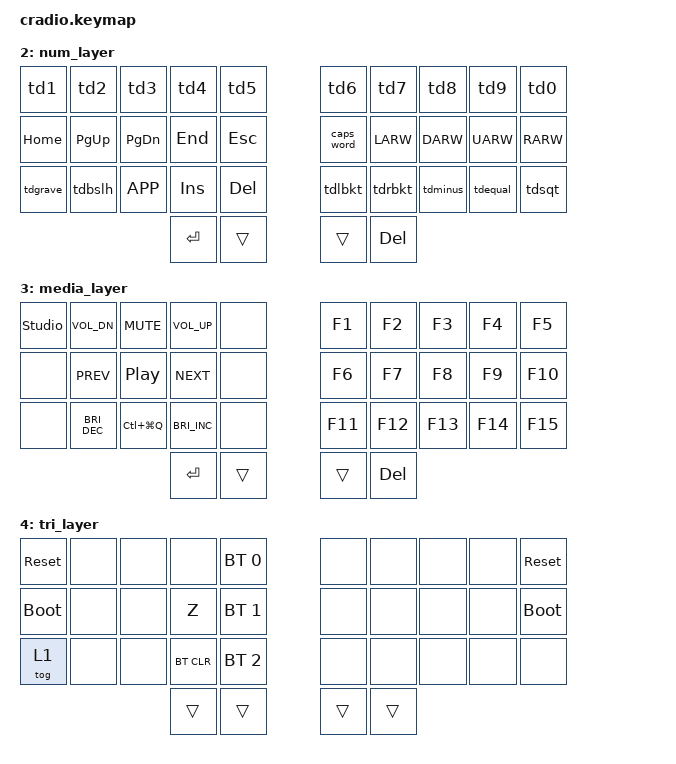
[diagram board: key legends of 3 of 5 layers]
// Copyright (c) 2022 The ZMK Contributors
// SPDX-License-Identifier: MIT

#include <behaviors.dtsi>
#include <dt-bindings/zmk/keys.h>
#include <dt-bindings/zmk/bt.h>

// Home row mods macro
#define HRML(k1,k2,k3,k4) &ht LGUI k1  &ht LALT k2  &ht LSHFT k3  &ht LCTRL k4
#define HRMR(k1,k2,k3,k4) &ht RCTRL k1  &ht RSHFT k2  &ht RALT k3  &ht RGUI k4

/ {
    behaviors {
        ht: hold_tap {
            compatible = "zmk,behavior-hold-tap";
            #binding-cells = <2>;
            flavor = "tap-preferred";
            tapping-term-ms = <220>;
            quick-tap-ms = <150>;
            require-prior-idle-ms = <100>;
            bindings = <&kp>, <&kp>;
        };

        td1: tap_dance_1 {
            compatible = "zmk,behavior-tap-dance";
            #binding-cells = <0>;
            tapping-term-ms = <200>;
            bindings = <&kp N1>, <&kp EXCL>;
        };

        td2: tap_dance_2 {
            compatible = "zmk,behavior-tap-dance";
            #binding-cells = <0>;
            tapping-term-ms = <200>;
            bindings = <&kp N2>, <&kp AT>;
        };

        td3: tap_dance_3 {
            compatible = "zmk,behavior-tap-dance";
            #binding-cells = <0>;
            tapping-term-ms = <200>;
            bindings = <&kp N3>, <&kp HASH>;
        };

        td4: tap_dance_4 {
            compatible = "zmk,behavior-tap-dance";
            #binding-cells = <0>;
            tapping-term-ms = <200>;
            bindings = <&kp N4>, <&kp DLLR>;
        };

        td5: tap_dance_5 {
            compatible = "zmk,behavior-tap-dance";
            #binding-cells = <0>;
            tapping-term-ms = <200>;
            bindings = <&kp N5>, <&kp PRCNT>;
        };

        td6: tap_dance_6 {
            compatible = "zmk,behavior-tap-dance";
            #binding-cells = <0>;
            tapping-term-ms = <200>;
            bindings = <&kp N6>, <&kp CARET>;
        };

        td7: tap_dance_7 {
            compatible = "zmk,behavior-tap-dance";
            #binding-cells = <0>;
            tapping-term-ms = <200>;
            bindings = <&kp N7>, <&kp AMPS>;
        };

        td8: tap_dance_8 {
            compatible = "zmk,behavior-tap-dance";
            #binding-cells = <0>;
            tapping-term-ms = <200>;
            bindings = <&kp N8>, <&kp STAR>;
        };

        td9: tap_dance_9 {
            compatible = "zmk,behavior-tap-dance";
            #binding-cells = <0>;
            tapping-term-ms = <200>;
            bindings = <&kp N9>, <&kp LPAR>;
        };

        td0: tap_dance_0 {
            compatible = "zmk,behavior-tap-dance";
            #binding-cells = <0>;
            tapping-term-ms = <200>;
            bindings = <&kp N0>, <&kp RPAR>;
        };

        tdgrave: tap_dance_grave {
            compatible = "zmk,behavior-tap-dance";
            #binding-cells = <0>;
            tapping-term-ms = <200>;
            bindings = <&kp GRAVE>, <&kp TILDE>;
        };

        tdbslh: tap_dance_bslh {
            compatible = "zmk,behavior-tap-dance";
            #binding-cells = <0>;
            tapping-term-ms = <200>;
            bindings = <&kp BSLH>, <&kp PIPE>;
        };

        tdlbkt: tap_dance_lbkt {
            compatible = "zmk,behavior-tap-dance";
            #binding-cells = <0>;
            tapping-term-ms = <200>;
            bindings = <&kp LBKT>, <&kp LBRC>;
        };

        tdrbkt: tap_dance_rbkt {
            compatible = "zmk,behavior-tap-dance";
            #binding-cells = <0>;
            tapping-term-ms = <200>;
            bindings = <&kp RBKT>, <&kp RBRC>;
        };

        tdminus: tap_dance_minus {
            compatible = "zmk,behavior-tap-dance";
            #binding-cells = <0>;
            tapping-term-ms = <200>;
            bindings = <&kp MINUS>, <&kp UNDER>;
        };

        tdequal: tap_dance_equal {
            compatible = "zmk,behavior-tap-dance";
            #binding-cells = <0>;
            tapping-term-ms = <200>;
            bindings = <&kp EQUAL>, <&kp PLUS>;
        };

        tdsqt: tap_dance_sqt {
            compatible = "zmk,behavior-tap-dance";
            #binding-cells = <0>;
            tapping-term-ms = <200>;
            bindings = <&kp SQT>, <&kp DQT>;
        };

        tdsemi: tap_dance_semi {
            compatible = "zmk,behavior-tap-dance";
            #binding-cells = <0>;
            tapping-term-ms = <200>;
            bindings = <&kp SEMI>, <&kp COLON>;
        };

        tdcomma: tap_dance_comma {
            compatible = "zmk,behavior-tap-dance";
            #binding-cells = <0>;
            tapping-term-ms = <200>;
            bindings = <&kp COMMA>, <&kp LT>;
        };

        tddot: tap_dance_dot {
            compatible = "zmk,behavior-tap-dance";
            #binding-cells = <0>;
            tapping-term-ms = <200>;
            bindings = <&kp DOT>, <&kp GT>;
        };

        tdfslh: tap_dance_fslh {
            compatible = "zmk,behavior-tap-dance";
            #binding-cells = <0>;
            tapping-term-ms = <200>;
            bindings = <&kp FSLH>, <&kp QMARK>;
        };
    };

    conditional_layers {
        compatible = "zmk,conditional-layers";
        tri_layer {
            if-layers = <2 3>;
            then-layer = <4>;
        };
    };

    keymap {
        compatible = "zmk,keymap";
        default_layer {
            bindings = <
        //╭──────────┬──────────┬──────────┬──────────┬──────────╮   ╭──────────┬──────────┬──────────┬──────────┬──────────╮
        //│  Q       │  W       │  F       │  P       │  B       │   │  J       │  L       │  U       │  Y       │  ;       │
            &kp Q      &kp W      &kp F      &kp P      &kp B          &kp J      &kp L      &kp U      &kp Y      &tdsemi
        //├──────────┼──────────┼──────────┼──────────┼──────────┤   ├──────────┼──────────┼──────────┼──────────┼──────────┤
        //│  A       │  R       │  S       │  T       │  G       │   │  M       │  N       │  E       │  I       │  O       │
            HRML(A,        R,         S,         T)     &kp G          &kp M      HRMR(N,        E,         I,        O)
        //├──────────┼──────────┼──────────┼──────────┼──────────┤   ├──────────┼──────────┼──────────┼──────────┼──────────┤
        //│  Z       │  X       │  C       │  D       │  V       │   │  K       │  H       │ , <      │ . >      │ / ?      │
            &kp Z      &kp X      &kp C      &kp D      &kp V          &kp K      &kp H      &tdcomma   &tddot     &tdfslh
        //╰──────────┴──────────┴──────────┼──────────┼──────────┤   ├──────────┼──────────┼──────────┴──────────┴──────────╯
                                            &kp SPACE  &lt 3 TAB     &lt 2 ENTER  &kp BSPC
        //                                 ╰──────────┴──────────╯   ╰──────────┴──────────╯
            >;
        };

        qwerty_layer {
            bindings = <
        //╭──────────┬──────────┬──────────┬──────────┬──────────╮   ╭──────────┬──────────┬──────────┬──────────┬──────────╮
        //│  Q       │  W       │  E       │  R       │  T       │   │  Y       │  U       │  I       │  O       │  P       │
            &kp Q      &kp W      &kp E      &kp R      &kp T          &kp Y      &kp U      &kp I      &kp O      &kp P
        //├──────────┼──────────┼──────────┼──────────┼──────────┤   ├──────────┼──────────┼──────────┼──────────┼──────────┤
        //│  A       │  S       │  D       │  F       │  G       │   │  H       │  J       │  K       │  L       │  ;       │
            HRML(A,        S,         D,         F)     &kp G          &kp H      HRMR(J,        K,         L,        SEMI)
        //├──────────┼──────────┼──────────┼──────────┼──────────┤   ├──────────┼──────────┼──────────┼──────────┼──────────┤
        //│  Z       │  X       │  C       │  V       │  B       │   │  N       │  M       │ , <      │ . >      │ / ?      │
            &kp Z      &kp X      &kp C      &kp V      &kp B          &kp N      &kp M      &tdcomma   &tddot     &tdfslh
        //╰──────────┴──────────┴──────────┼──────────┼──────────┤   ├──────────┼──────────┼──────────┴──────────┴──────────╯
                                            &kp SPACE  &lt 3 TAB     &lt 2 ENTER  &kp BSPC
        //                                 ╰──────────┴──────────╯   ╰──────────┴──────────╯
            >;
        };

        num_layer {
            bindings = <
        //╭──────────┬──────────┬──────────┬──────────┬──────────╮   ╭──────────┬──────────┬──────────┬──────────┬──────────╮
        //│  1       │  2       │  3       │  4       │  5       │   │  6       │  7       │  8       │  9       │  0       │
            &td1       &td2       &td3       &td4       &td5           &td6       &td7       &td8       &td9       &td0 
        //├──────────┼──────────┼──────────┼──────────┼──────────┤   ├──────────┼──────────┼──────────┼──────────┼──────────┤
        //│ ESC      │ HOME     │ PAGE DN  │ PAGE UP  │ END      │   │ LEFT     │ DOWN     │ UP       │ RIGHT    │  CAPS    │
           &kp HOME   &kp PG_UP  &kp PG_DN  &kp END    &kp ESC        &caps_word &kp LARW   &kp DARW   &kp UARW   &kp RARW
        //├──────────┼──────────┼──────────┼──────────┼──────────┤   ├──────────┼──────────┼──────────┼──────────┼──────────┤
        //│ `        │ \        │ MENU     │ INS      │ DEL      │   │ [        │ ]        │  -       │  =       │  ' "     │
            &tdgrave   &tdbslh    &kp K_APP  &kp INS    &kp DEL        &tdlbkt    &tdrbkt    &tdminus   &tdequal   &tdsqt
        //╰──────────┴──────────┴──────────┼──────────┼──────────┤   ├──────────┼──────────┼──────────┴──────────┴──────────╯
                                            &kp ENTER  &trans        &trans     &kp DEL
        //                                 ╰──────────┴──────────╯   ╰──────────┴──────────╯
            >;
        };

        media_layer {
            bindings = <
        //╭──────────┬──────────┬──────────┬──────────┬──────────╮   ╭──────────┬──────────┬──────────┬──────────┬──────────╮
        //│          │          │          │          │          │   │          │          │          │          │          │
        &studio_unlock &kp C_VOL_DN &kp C_MUTE &kp C_VOL_UP &none     &kp F1     &kp F2     &kp F3     &kp F4     &kp F5
        //├──────────┼──────────┼──────────┼──────────┼──────────┤   ├──────────┼──────────┼──────────┼──────────┼──────────┤
        //│          │          │          │          │          │   │          │          │          │          │          │
            &none    &kp C_PREV  &kp C_PP   &kp C_NEXT  &none        &kp F6     &kp F7     &kp F8     &kp F9     &kp F10
        //├──────────┼──────────┼──────────┼──────────┼──────────┤   ├──────────┼──────────┼──────────┼──────────┼──────────┤
        //│          │          │          │          │          │   │          │          │          │          │          │
            &none  &kp C_BRI_DEC &kp LC(LG(Q)) &kp C_BRI_INC &none        &kp F11    &kp F12    &kp F13    &kp F14    &kp F15
        //╰──────────┴──────────┴──────────┼──────────┼──────────┤   ├──────────┼──────────┼──────────┴──────────┴──────────╯
                                            &kp ENTER   &trans         &trans     &kp DEL
        //                                 ╰──────────┴──────────╯   ╰──────────┴──────────╯
            >;
        };

        tri_layer {
            bindings = <
        //╭──────────┬──────────┬──────────┬──────────┬──────────╮   ╭──────────┬──────────┬──────────┬──────────┬──────────╮
        //│ RESET    │          │          │          │PROFILE 0 │   │          │          │          │          │  RESET   │
           &sys_reset  &none     &none     &none    &bt BT_SEL 0    &none     &none     &none     &none    &sys_reset
        //├──────────┼──────────┼──────────┼──────────┼──────────┤   ├──────────┼──────────┼──────────┼──────────┼──────────┤
        //│BOOTLOADER│          │          │  Z       │PROFILE 1 │   │          │          │          │          │BOOTLOADER│
          &bootloader  &none     &none     &kp Z    &bt BT_SEL 1    &none     &none     &none     &none    &bootloader
        //├──────────┼──────────┼──────────┼──────────┼──────────┤   ├──────────┼──────────┼──────────┼──────────┼──────────┤
        //│          │          │          │ CLEAR BT │PROFILE 2 │   │          │          │          │          │          │
            &tog 1     &none      &none     &bt BT_CLR &bt BT_SEL 2     &none      &none      &none      &none      &none
        //╰──────────┴──────────┴──────────┼──────────┼──────────┤   ├──────────┼──────────┼──────────┴──────────┴──────────╯
                                             &trans     &trans         &trans     &trans
        //                                 ╰──────────┴──────────╯   ╰──────────┴──────────╯
            >;
        };
    };
};
